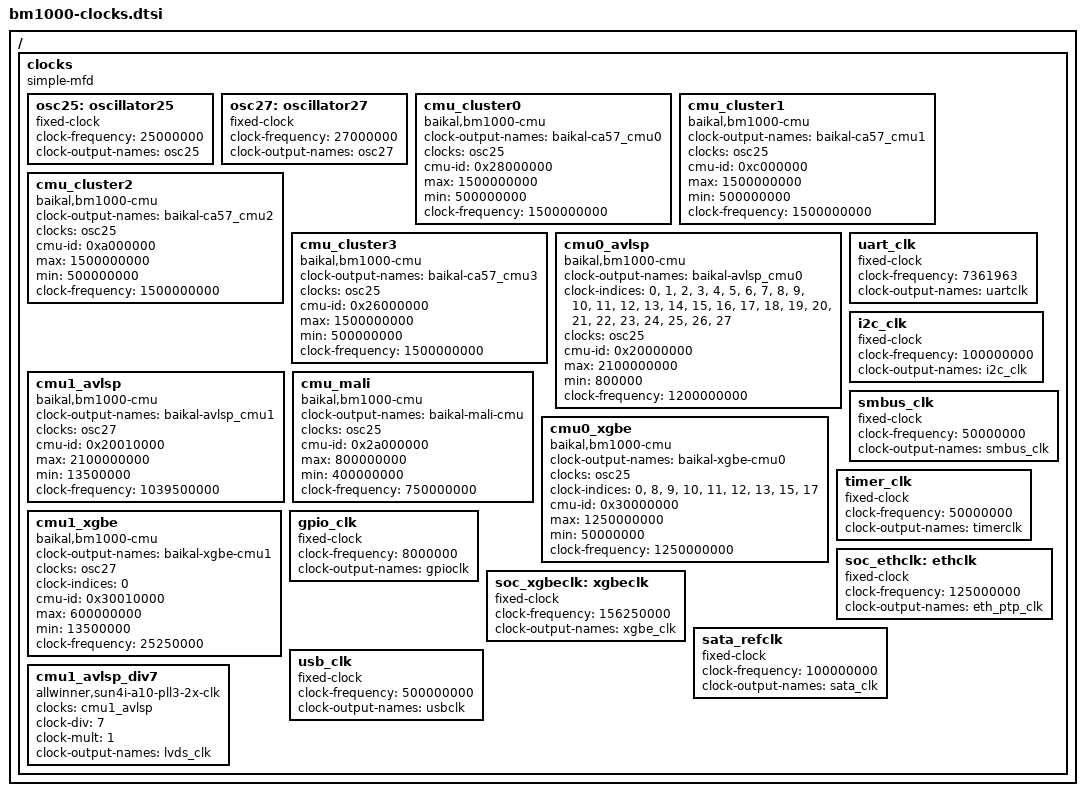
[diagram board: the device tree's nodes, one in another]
// SPDX-License-Identifier: GPL-2.0
/*
 * Baikal-M SoC clock tree
 */

/ {

	clocks {
		compatible = "simple-mfd";

		osc25: oscillator25 { /* external oscillator */
			compatible = "fixed-clock";
			#clock-cells = <0>;
			clock-frequency  = <25000000>;
			clock-output-names = "osc25";
		};

		osc27: oscillator27 { /* external oscillator */
			compatible = "fixed-clock";
			#clock-cells = <0>;
			clock-frequency  = <27000000>;
			clock-output-names = "osc27";
		};

		cmu_cluster0: cmu_cluster0 {
			compatible = "baikal,bm1000-cmu", "baikal,cmu";
			clock-output-names = "baikal-ca57_cmu0";
			#clock-cells = <0>;
			clocks = <&osc25>;
			cmu-id = <0x28000000>;
			max = <1500000000>;
			min = <500000000>;
			clock-frequency = <1500000000>;
		};

		cmu_cluster1: cmu_cluster1 {
			compatible = "baikal,bm1000-cmu", "baikal,cmu";
			clock-output-names = "baikal-ca57_cmu1";
			#clock-cells = <0>;
			clocks = <&osc25>;
			cmu-id = <0xc000000>;
			max = <1500000000>;
			min = <500000000>;
			clock-frequency = <1500000000>;
		};

		cmu_cluster2: cmu_cluster2 {
			compatible = "baikal,bm1000-cmu", "baikal,cmu";
			clock-output-names = "baikal-ca57_cmu2";
			#clock-cells = <0>;
			clocks = <&osc25>;
			cmu-id = <0xa000000>;
			max = <1500000000>;
			min = <500000000>;
			clock-frequency = <1500000000>;
		};

		cmu_cluster3: cmu_cluster3 {
			compatible = "baikal,bm1000-cmu", "baikal,cmu";
			clock-output-names = "baikal-ca57_cmu3";
			#clock-cells = <0>;
			clocks = <&osc25>;
			cmu-id = <0x26000000>;
			max = <1500000000>;
			min = <500000000>;
			clock-frequency = <1500000000>;
		};

		cmu0_avlsp: cmu0_avlsp {
			compatible = "baikal,bm1000-cmu", "baikal,cmu";
			#clock-cells = <1>;
			clock-output-names = "baikal-avlsp_cmu0";
			clock-names =
				"gpio",         // <0>
				"uart1",        // <1>
				"uart2",        // <2>
				"apb",          // <3>
				"spi",          // <4>
				"espi",         // <5>
				"i2c1",         // <6>
				"i2c2",         // <7>
				"timer1",       // <8>
				"timer2",       // <9>
				"timer3",       // <10>
				"timer4",       // <11>
				"dmac",         // <12>
				"smbus1",       // <13>
				"smbus2",       // <14>
				"hda_sys_clk",  // <15>
				"hda_clk48",    // <16>
				"mshc_axi",     // <17>
				"mshc_ahb",     // <18>
				"mshc_tx_x2",   // <19>
				"mshc_b",       // <20>
				"mshc_tm",      // <21>
				"mshc_cqetm",   // <22>
				"hwa_clu",      // <23>
				"hwa_clu_hf",   // <24>
				"hwa_axi",      // <25>
				"vdu_axi",      // <26>
				"smmu";         // <27>
			clock-indices =
				<0>, <1>, <2>, <3>, <4>, <5>, <6>, <7>, <8>, <9>, <10>,
				<11>, <12>, <13>, <14>, <15>, <16>, <17>, <18>, <19>,
				<20>, <21>, <22>, <23>, <24>, <25>, <26>, <27>;
			clocks = <&osc25>;
			cmu-id = <0x20000000>;
			max = <2100000000>;
			min = <800000>;
			clock-frequency = <1200000000>;
		};

		cmu1_avlsp: cmu1_avlsp {
			compatible = "baikal,bm1000-cmu", "baikal,cmu";
			clock-output-names = "baikal-avlsp_cmu1";
			#clock-cells = <0>;
			clocks = <&osc27>;
			cmu-id = <0x20010000>;
			max = <2100000000>;
			min = <13500000>;
			clock-frequency = <1039500000>;
		};

		cmu_mali: cmu_mali {
			compatible = "baikal,bm1000-cmu", "baikal,cmu";
			clock-output-names = "baikal-mali-cmu";
			#clock-cells = <0>;
			clocks = <&osc25>;
			clock-names = "aclk";
			cmu-id = <0x2a000000>;
			max = <800000000>;
			min = <400000000>;
			clock-frequency = <750000000>;
		};

		cmu0_xgbe: cmu0_xgbe {
			compatible = "baikal,bm1000-cmu", "baikal,cmu";
			clock-output-names = "baikal-xgbe-cmu0";
			#clock-cells = <1>;
			clocks = <&osc25>;
			clock-names = "csr50mhz", "gmac0_aclk", "gmac0_ptp", "gmac0_tx2", "gmac1_aclk", "gmac1_ptp", "gmac1_tx2", "hdmi_aclk", "isfr";
			clock-indices = <0>, <8>, <9>, <10>, <11>, <12>, <13>, <15>, <17>;
			cmu-id = <0x30000000>;
			max = <1250000000>;
			min = <50000000>;
			clock-frequency = <1250000000>;
		};

		cmu1_xgbe: cmu1_xgbe {
			compatible = "baikal,bm1000-cmu", "baikal,cmu";
			clock-output-names = "baikal-xgbe-cmu1";
			#clock-cells = <1>;
			clocks = <&osc27>;
			clock-indices = <0>;
			clock-names = "pixelclk";
			cmu-id = <0x30010000>;
			max = <600000000>;
			min = <13500000>;
			clock-frequency = <25250000>;
		};

		/* Fixed versions of clock channels. May be used when
		   driver requires a clock to exist but does not need
		   to change frequency. */

		/* UART clock 7.35MHz */
		uart_clk: uart_clk {
			compatible = "fixed-clock";
			#clock-cells = <0>;
			clock-frequency = <7361963>;
			clock-output-names = "uartclk";
		};

		/* I2C clock 100MHz */
		i2c_clk: i2c_clk {
			compatible = "fixed-clock";
			#clock-cells = <0>;
			clock-frequency = <100000000>;
			clock-output-names = "i2c_clk";
		};

		/* SMBus clock 50MHz */
		smbus_clk: smbus_clk {
			compatible = "fixed-clock";
			#clock-cells = <0>;
			clock-frequency = <50000000>;
			clock-output-names = "smbus_clk";
		};

		/* Timer 1-4 clock 50MHz */
		timer_clk: timer_clk {
			compatible = "fixed-clock";
			#clock-cells = <0>;
			clock-frequency = <50000000>;
			clock-output-names = "timerclk";
		};

		/* GPIO clock 8MHz */
		gpio_clk: gpio_clk {
			compatible = "fixed-clock";
			#clock-cells = <0>;
			clock-frequency = <8000000>;
			clock-output-names = "gpioclk";
		};

		soc_ethclk: ethclk {
			compatible = "fixed-clock";
			#clock-cells = <0>;
			clock-frequency = <125000000>;
			clock-output-names = "eth_ptp_clk";
		};

		soc_xgbeclk: xgbeclk {
			compatible = "fixed-clock";
			#clock-cells = <0>;
			clock-frequency = <156250000>;
			clock-output-names = "xgbe_clk";
		};

		sata_refclk: sata_refclk {
			compatible = "fixed-clock";
			#clock-cells = <0>;
			clock-frequency = <100000000>;
			clock-output-names = "sata_clk";
		};

		usb_clk: usb_clk {
			#clock-cells = <0>;
			compatible = "fixed-clock";
			clock-names = "usbclk";
			clock-frequency = <500000000>;
			clock-output-names = "usbclk";
		};

		cmu1_avlsp_div7: cmu1_avlsp_div7 {
			compatible = "allwinner,sun4i-a10-pll3-2x-clk", "fixed-factor-clock";
			clocks = <&cmu1_avlsp>;
			#clock-cells = <0>;
			clock-div = <7>;
			clock-mult = <1>;
			clock-output-names = "lvds_clk";
		};
	};
};
